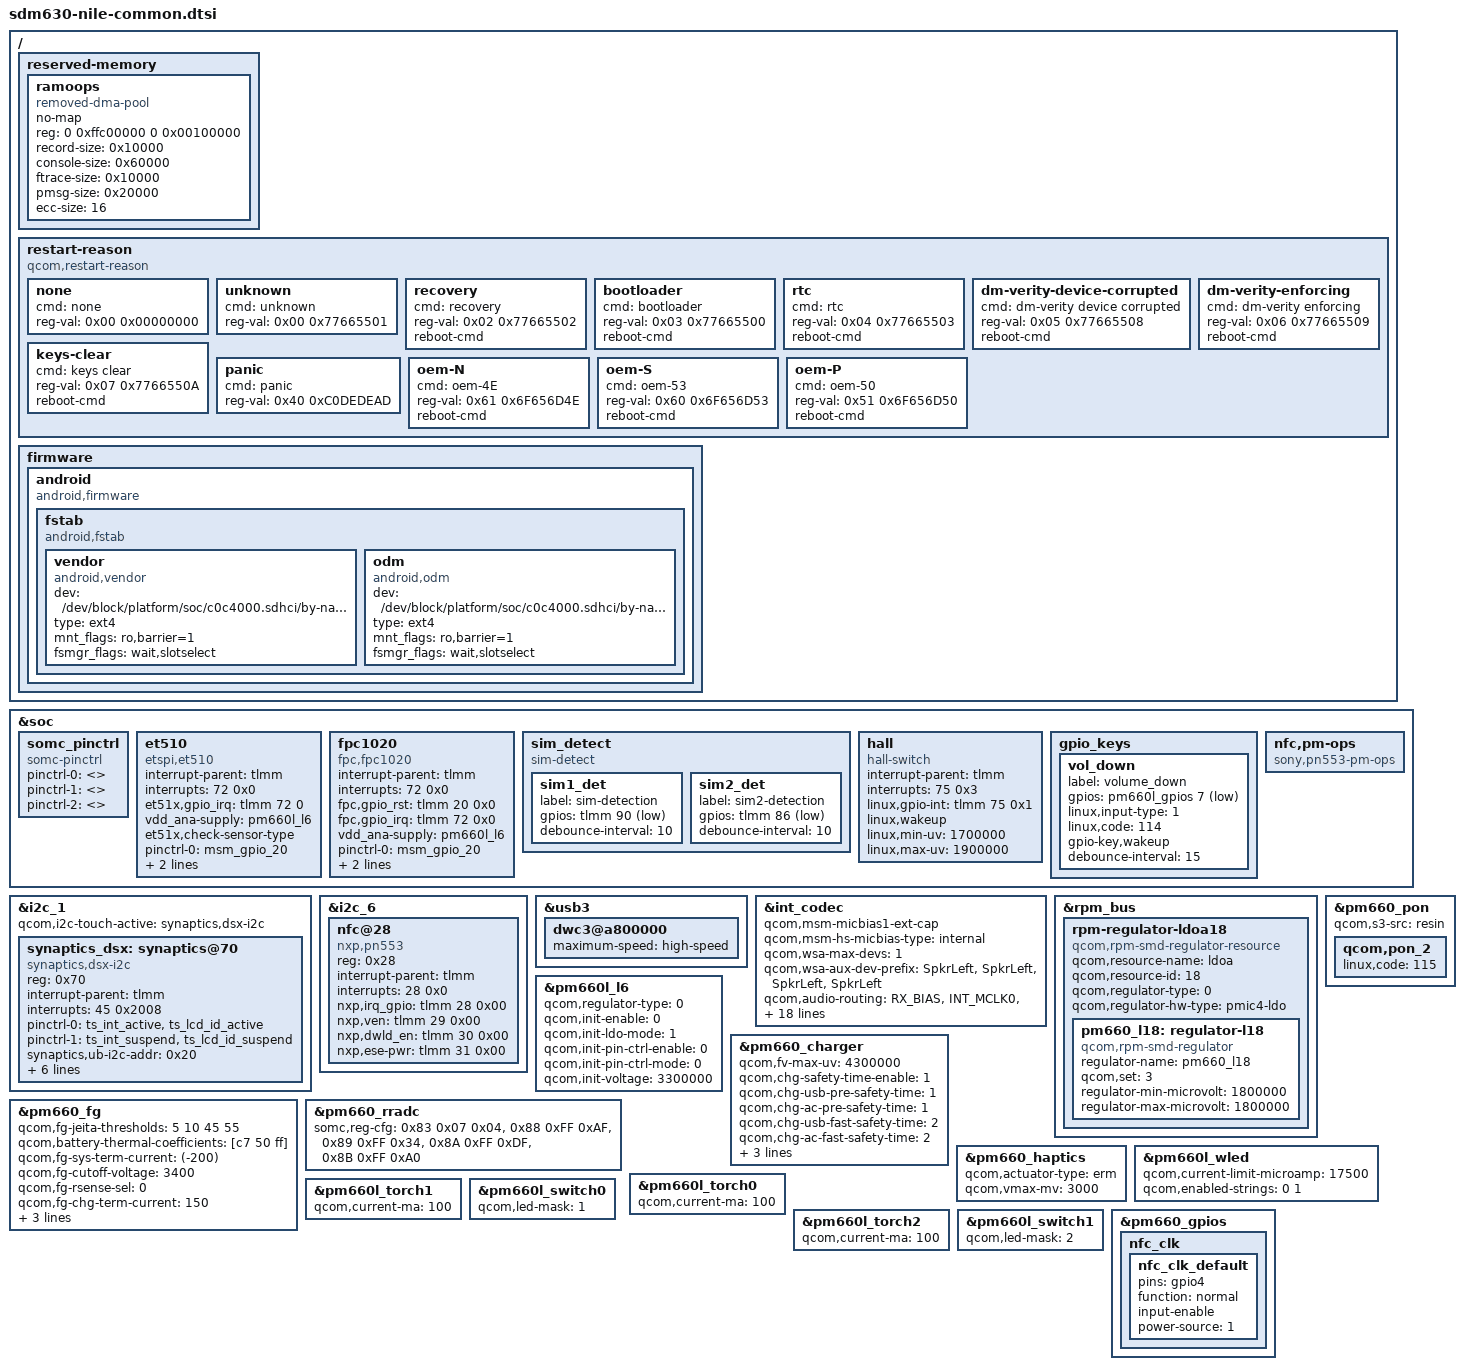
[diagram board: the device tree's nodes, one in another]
// SPDX-License-Identifier: GPL-2.0-only
/*
 * Copyright (c) 2017-2021, The Linux Foundation. All rights reserved.
 */

#include "sdm630-nile-pinctrl.dtsi"

/ {
	reserved-memory {
		ramoops {
			compatible = "removed-dma-pool", "ramoops";
			no-map;
			reg = <0 0xffc00000 0 0x00100000>;
			record-size = <0x10000>;
			console-size = <0x60000>;
			ftrace-size = <0x10000>;
			pmsg-size = <0x20000>;
			ecc-size = <16>;
		};
	};

	restart-reason {
		compatible = "qcom,restart-reason";

		none {
			cmd = "none";
			reg-val = <0x00 0x00000000>;
		};

		unknown {
			cmd = "unknown";
			reg-val = <0x00 0x77665501>;
		};

		recovery {
			cmd = "recovery";
			reg-val = <0x02 0x77665502>;
			reboot-cmd;
		};

		bootloader {
			cmd = "bootloader";
			reg-val = <0x03 0x77665500>;
			reboot-cmd;
		};

		rtc {
			cmd = "rtc";
			reg-val = <0x04 0x77665503>;
			reboot-cmd;
		};

		dm-verity-device-corrupted {
			cmd = "dm-verity device corrupted";
			reg-val = <0x05 0x77665508>;
			reboot-cmd;
		};

		dm-verity-enforcing {
			cmd = "dm-verity enforcing";
			reg-val = <0x06 0x77665509>;
			reboot-cmd;
		};

		keys-clear {
			cmd = "keys clear";
			reg-val = <0x07 0x7766550A>;
			reboot-cmd;
		};

		panic {
			cmd = "panic";
			reg-val = <0x40 0xC0DEDEAD>;
		};

		oem-N {
			cmd = "oem-4E";
			reg-val = <0x61 0x6F656D4E>;
			reboot-cmd;
		};

		oem-S {
			cmd = "oem-53";
			reg-val = <0x60 0x6F656D53>;
			reboot-cmd;
		};

		oem-P {
			cmd = "oem-50";
			reg-val = <0x51 0x6F656D50>;
			reboot-cmd;
		};
	};

	firmware: firmware {
		android {
			compatible = "android,firmware";

			fstab {
				compatible = "android,fstab";

				vendor {
					compatible = "android,vendor";
					dev = "/dev/block/platform/soc/c0c4000.sdhci/by-name/vendor";
					type = "ext4";
					mnt_flags = "ro,barrier=1";
					fsmgr_flags = "wait,slotselect";
					status = "ok";
				};

				odm {
					compatible = "android,odm";
					dev = "/dev/block/platform/soc/c0c4000.sdhci/by-name/oem";
					type = "ext4";
					mnt_flags = "ro,barrier=1";
					fsmgr_flags = "wait,slotselect";
					status = "ok";
				};
			};
		};
	};
};

&soc {
	somc_pinctrl: somc_pinctrl {
		compatible = "somc-pinctrl";
		pinctrl-names = "platform_common_default",
						"product_common_default",
						"variant_default";
		pinctrl-0 = <>;

		/* If product common default setting is needed,
			fill pinctrl-1 value in <product>_common.dtsi */
		pinctrl-1 = <>;

		/* If variant specific default setting is needed,
			fill pinctrl-2 value in <variant>.dtsi */
		pinctrl-2 = <>;
	};

	et510 {
		compatible = "etspi,et510";
		interrupt-parent = <&tlmm>;
		interrupts = <72 0x0>;
		et51x,gpio_irq    = <&tlmm 72 0>;
		vdd_ana-supply = <&pm660l_l6>;
		et51x,check-sensor-type;

		pinctrl-names = "et51x_reset_reset",
			"et51x_reset_active",
			"et51x_irq_active";

		pinctrl-0 = <&msm_gpio_20>;
		pinctrl-1 = <&msm_gpio_20_output_high>;
		pinctrl-2 = <&msm_gpio_72>;
	};

	fpc1020 {
		compatible = "fpc,fpc1020";
		interrupt-parent = <&tlmm>;
		interrupts = <72 0x0>;
		fpc,gpio_rst    = <&tlmm 20 0x0>;
		fpc,gpio_irq    = <&tlmm 72 0x0>;
		vdd_ana-supply = <&pm660l_l6>;

		pinctrl-names = "fpc1145_reset_reset",
			"fpc1145_reset_active",
			"fpc1145_irq_active";

		pinctrl-0 = <&msm_gpio_20>;
		pinctrl-1 = <&msm_gpio_20_output_high>;
		pinctrl-2 = <&msm_gpio_72>;
	};

	sim_detect {
		compatible = "sim-detect";

		sim1_det {
			label = "sim-detection";
			gpios = <&tlmm 90 0x1>;
			debounce-interval = <10>;
		};

		sim2_det {
			label = "sim2-detection";
			gpios = <&tlmm 86 0x1>;
			debounce-interval = <10>;
		};
	};

	hall {
		compatible = "hall-switch";
		interrupt-parent = <&tlmm>;
		interrupts = <75 0x3>;
		//vddio-supply = <&pm660l_l14>;
		linux,gpio-int = <&tlmm 75 0x1>;
		linux,wakeup;
		linux,min-uv = <1700000>;
		linux,max-uv = <1900000>;
	};

	gpio_keys {
		/delete-node/ vol_up;
		vol_down {
			label = "volume_down";
			gpios = <&pm660l_gpios 7 0x1>;
			linux,input-type = <1>;
			linux,code = <114>;
			gpio-key,wakeup;
			debounce-interval = <15>;
		};
	};

	nfc,pm-ops {
		compatible = "sony,pn553-pm-ops";
	};
};

&i2c_1 {
	status = "okay";
	qcom,i2c-touch-active = "synaptics,dsx-i2c";

	synaptics_dsx: synaptics@70 {
		compatible = "synaptics,dsx-i2c";
		reg = <0x70>;
		interrupt-parent = <&tlmm>;
		interrupts = <45 0x2008>;
		pinctrl-names = "pmx_ts_active", "pmx_ts_suspend";
		pinctrl-0 = <&ts_int_active &ts_lcd_id_active>;
		pinctrl-1 = <&ts_int_suspend &ts_lcd_id_suspend>;
		synaptics,ub-i2c-addr = <0x20>;
		synaptics,irq-gpio = <&tlmm 45 0x2008>; /* IRQF_ONESHOT | IRQF_TRIGGER_LOW */
		synaptics,irq-on-state = <0>;
		synaptics,power-delay-ms = <200>;
		synaptics,reset-delay-ms = <200>;
		synaptics,reset-on-state = <0>;
		synaptics,reset-active-ms = <20>;
	};
};

&i2c_6 {
	/delete-node/ nq@28;

	nfc@28 {
		compatible = "nxp,pn553";
		reg = <0x28>;
		interrupt-parent = <&tlmm>;
		interrupts = <28 0x0>;
		nxp,irq_gpio = <&tlmm 28 0x00>;
		nxp,ven = <&tlmm 29 0x00>;
		nxp,dwld_en = <&tlmm 30 0x00>;
		nxp,ese-pwr = <&tlmm 31 0x00>;
	};
};

&usb3 {
	dwc3@a800000 {
		maximum-speed = "high-speed";
	};
};

&int_codec {
	status = "ok";
	/delete-property/ qcom,msm-micbias2-ext-cap;
	qcom,msm-micbias1-ext-cap;
	qcom,msm-hs-micbias-type = "internal";

	qcom,wsa-max-devs = <1>;
	qcom,wsa-aux-dev-prefix = "SpkrLeft", "SpkrLeft",
				  "SpkrLeft", "SpkrLeft";

	qcom,audio-routing =
		"RX_BIAS", "INT_MCLK0",
		"SPK_RX_BIAS", "INT_MCLK0",
		"INT_LDO_H", "INT_MCLK0",
		"RX_I2S_CLK", "INT_MCLK0",
		"TX_I2S_CLK", "INT_MCLK0",
		"MIC BIAS External", "Handset Mic",
		"MIC BIAS Internal2", "Headset Mic",
		"MIC BIAS External", "Secondary Mic",
		"AMIC1", "MIC BIAS External",
		"AMIC2", "MIC BIAS Internal2",
		"AMIC3", "MIC BIAS External",
		"DMIC1", "MIC BIAS External",
		"MIC BIAS External", "Digital Mic1",
		"DMIC2", "MIC BIAS External",
		"MIC BIAS External", "Digital Mic2",
		"DMIC3", "MIC BIAS External",
		"MIC BIAS External", "Digital Mic3",
		"DMIC4", "MIC BIAS External",
		"MIC BIAS External", "Digital Mic4",
		"SpkrLeft IN", "SPK1 OUT",
		"SpkrRight IN", "SPK2 OUT",
		"PDM_IN_RX1", "PDM_OUT_RX1",
		"PDM_IN_RX2", "PDM_OUT_RX2",
		"PDM_IN_RX3", "PDM_OUT_RX3",
		"ADC1_IN", "ADC1_OUT",
		"ADC2_IN", "ADC2_OUT",
		"ADC3_IN", "ADC3_OUT";
};

&rpm_bus {
	rpm-regulator-ldoa18 {
		compatible = "qcom,rpm-smd-regulator-resource";
		qcom,resource-name = "ldoa";
		qcom,resource-id = <18>;
		qcom,regulator-type = <0>;
		qcom,regulator-hw-type = "pmic4-ldo";
		status = "okay";
		pm660_l18: regulator-l18 {
			compatible = "qcom,rpm-smd-regulator";
			regulator-name = "pm660_l18";
			qcom,set = <3>;
			regulator-min-microvolt = <1800000>;
			regulator-max-microvolt = <1800000>;
			status = "okay";
		};
	};
};
&pm660l_l6 {
	qcom,regulator-type = <0>;  /* LDO */
	qcom,init-enable = <0>;
	qcom,init-ldo-mode = <1>;
	qcom,init-pin-ctrl-enable = <0>;
	qcom,init-pin-ctrl-mode = <0>;
	qcom,init-voltage = <3300000>;
};

/* PM660 */
&pm660_pon {
	/delete-property/ kpdpwr-sw-debounce;
	qcom,s3-src = "resin";
	qcom,pon_2 {
		linux,code = <115>;
	};
};

&pm660_charger {
	qcom,fv-max-uv = <4300000>;
	qcom,chg-safety-time-enable = <1>;
	qcom,chg-usb-pre-safety-time = <1>;
	qcom,chg-ac-pre-safety-time = <1>;
	qcom,chg-usb-fast-safety-time = <2>;
	qcom,chg-ac-fast-safety-time = <2>;
	qcom,float-option = <2>;
	qcom,thermal-mitigation = <2400000 1000000 500000 200000>;
};

&pm660_fg {
	qcom,fg-jeita-thresholds = <5 10 45 55>;
	qcom,battery-thermal-coefficients = [c7 50 ff];
	qcom,fg-sys-term-current = <(-200)>;
	qcom,fg-cutoff-voltage = <3400>;
	qcom,fg-rsense-sel = <0>;
	qcom,fg-chg-term-current = <150>;
	qcom,fg-force-load-profile;
	qcom,slope-limit-temp-threshold = <10>;
	qcom,slope-limit-coeffs = <1 1 1 1>;
};

&pm660_rradc {
	somc,reg-cfg =
	      /* addr mask value */
	      <0x83 0x07 0x04>, /* FG_ADC_RR_AUX_THERM_CFG */
	      <0x88 0xFF 0xAF>, /* FG_ADC_RR_AUX_THERM_C1 */
	      <0x89 0xFF 0x34>, /* FG_ADC_RR_AUX_THERM_C2 */
	      <0x8A 0xFF 0xDF>, /* FG_ADC_RR_AUX_THERM_C3 */
	      <0x8B 0xFF 0xA0>; /* FG_ADC_RR_AUX_THERM_HALF_RANGE */
};

/* PM660 */
&pm660_haptics {
	qcom,actuator-type = "erm";
	qcom,vmax-mv = <3000>;
};

/* PM660L */
&pm660l_wled {
	qcom,current-limit-microamp = <17500>;
	qcom,enabled-strings = <0 1>;

	/delete-property/ qcom,auto-calibration;
};

&pm660l_torch0 {
	qcom,current-ma = <100>;
};

&pm660l_torch1 {
	qcom,current-ma = <100>;
};

&pm660l_torch2 {
	qcom,current-ma = <100>;
};

&pm660l_switch0 {
	qcom,led-mask = <1>;
};

&pm660l_switch1 {
	qcom,led-mask = <2>;
};

&pm660_gpios {
	/* GPIO 4 (NFC_CLK_REQ) */
	nfc_clk {
		nfc_clk_default: nfc_clk_default {
			pins = "gpio4";
			function = "normal";
			input-enable;
			power-source = <1>;
		};
	};
};
